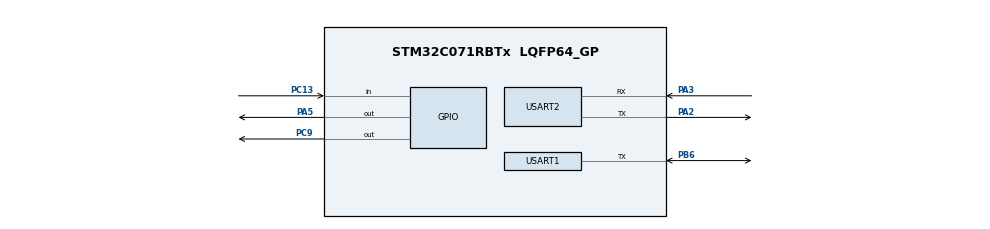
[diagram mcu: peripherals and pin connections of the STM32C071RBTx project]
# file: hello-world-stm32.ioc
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Mcu.Family=STM32C0
Mcu.Name=STM32C071RBTx
Mcu.Package=LQFP64_GP
NUCLEO-C071RB.BUTTON=1
NUCLEO-C071RB.LD1=true
NUCLEO-C071RB.LD2=true
NUCLEO-C071RB.VCP=false
NVIC.EXTI4_15_IRQn=true\:0\:0\:false\:false\:true\:false\:true\:true
NVIC.USART1_IRQn=true\:0\:0\:false\:false\:true\:true\:true\:true
NVIC.USART2_IRQn=true\:0\:0\:false\:false\:true\:true\:true\:true
PA13.Mode=Serial_Wire
PA13.Signal=DEBUG_SWDIO
PA14-BOOT0.Mode=Serial_Wire
PA14-BOOT0.Signal=DEBUG_SWCLK
PA2.Mode=Asynchronous
PA2.Signal=USART2_TX
PA3.Mode=Asynchronous
PA3.Signal=USART2_RX
PA5.Signal=GPIO_Output
PB6.Mode=Half_duplex(single_wire_mode)
PB6.Signal=USART1_TX
PB7.Signal=USART1_RX
PC13.Signal=GPIO_Input
PC9.Signal=GPIO_Output
ProjectManager.HeapSize=0x2000
ProjectManager.StackSize=0x400
ProjectManager.TargetToolchain=Makefile
RCC.ADCFreq_Value=48000000
RCC.AHBFreq_Value=48000000
RCC.CortexFreq_Value=48000000
RCC.EXTERNAL_CLOCK_VALUE=12288000
RCC.HCLKFreq_Value=48000000
RCC.HSE_VALUE=8000000
RCC.HSI48_VALUE=48000000
RCC.HSISYSCLKDivider=RCC_HSI_DIV1
RCC.HSI_VALUE=48000000
RCC.LSE_VALUE=32768
RCC.SYSCLKFreq_VALUE=48000000
USART1.DataInvertParam=ADVFEATURE_DATAINV_DISABLE
USART1.TxPinLevelInvertParam=ADVFEATURE_TXINV_DISABLE
USART1.VirtualMode-Half_duplex(single_wire_mode)=VM_ASYNC
USART2.VirtualMode-Asynchronous=VM_ASYNC
VP_NUCLEO-C071RB_VS_BSP_COMMON.Mode=COMMON
board=NUCLEO-C071RB

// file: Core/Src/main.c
/* USER CODE BEGIN Header */
/**
  ******************************************************************************
  * @file           : main.c
  * @brief          : Main program body
  ******************************************************************************
  * @attention
  *
  * Copyright (c) 2025 STMicroelectronics.
  * All rights reserved.
  *
  * This software is licensed under terms that can be found in the LICENSE file
  * in the root directory of this software component.
  * If no LICENSE file comes with this software, it is provided AS-IS.
  *
  ******************************************************************************
  */
/* USER CODE END Header */
#include "main.h"

/* USER CODE BEGIN Includes */
#include "StmSupervising.h"
/* USER CODE END Includes */

UART_HandleTypeDef huart1;
UART_HandleTypeDef huart2;

void SystemClock_Config(void);
static void MX_GPIO_Init(void);
static void MX_USART1_UART_Init(void);
static void MX_USART2_UART_Init(void);

int main(void)
{

  /* MCU Configuration--------------------------------------------------------*/

  /* Reset of all peripherals, Initializes the Flash interface and the Systick. */
  HAL_Init();

  /* Configure the system clock */
  SystemClock_Config();

  /* Initialize all configured peripherals */
  MX_GPIO_Init();
  MX_USART1_UART_Init();
  MX_USART2_UART_Init();

  /* Initialize leds */
  BSP_LED_Init(LED_GREEN);
  BSP_LED_Init(LED_BLUE);

  /* Initialize USER push-button, will be used to trigger an interrupt each time it's pressed.*/
  BSP_PB_Init(BUTTON_USER, BUTTON_MODE_EXTI);

  /* Infinite loop */
  /* USER CODE BEGIN WHILE */
  StmSupervising *pApp = StmSupervising::create();
  while (1)
  {
    pApp->treeTick();
    /* USER CODE END WHILE */

  }
}

void SystemClock_Config(void)
{
  RCC_OscInitTypeDef RCC_OscInitStruct = {0};
  RCC_ClkInitTypeDef RCC_ClkInitStruct = {0};

  __HAL_FLASH_SET_LATENCY(FLASH_LATENCY_1);

  /** Initializes the RCC Oscillators according to the specified parameters
  * in the RCC_OscInitTypeDef structure.
  */
  RCC_OscInitStruct.OscillatorType = RCC_OSCILLATORTYPE_HSI;
  RCC_OscInitStruct.HSIState = RCC_HSI_ON;
  RCC_OscInitStruct.HSIDiv = RCC_HSI_DIV1;
  RCC_OscInitStruct.HSICalibrationValue = RCC_HSICALIBRATION_DEFAULT;
  if (HAL_RCC_OscConfig(&RCC_OscInitStruct) != HAL_OK)
  {
    Error_Handler();
  }

  /** Initializes the CPU, AHB and APB buses clocks
  */
  RCC_ClkInitStruct.ClockType = RCC_CLOCKTYPE_HCLK|RCC_CLOCKTYPE_SYSCLK
                              |RCC_CLOCKTYPE_PCLK1;
  RCC_ClkInitStruct.SYSCLKSource = RCC_SYSCLKSOURCE_HSI;
  RCC_ClkInitStruct.SYSCLKDivider = RCC_SYSCLK_DIV1;
  RCC_ClkInitStruct.AHBCLKDivider = RCC_HCLK_DIV1;
  RCC_ClkInitStruct.APB1CLKDivider = RCC_APB1_DIV1;

  if (HAL_RCC_ClockConfig(&RCC_ClkInitStruct, FLASH_LATENCY_1) != HAL_OK)
  {
    Error_Handler();
  }
}

static void MX_USART1_UART_Init(void)
{

  huart1.Instance = USART1;
  huart1.Init.BaudRate = 115200;
  huart1.Init.WordLength = UART_WORDLENGTH_8B;
  huart1.Init.StopBits = UART_STOPBITS_1;
  huart1.Init.Parity = UART_PARITY_NONE;
  huart1.Init.Mode = UART_MODE_TX_RX;
  huart1.Init.HwFlowCtl = UART_HWCONTROL_NONE;
  huart1.Init.OverSampling = UART_OVERSAMPLING_16;
  huart1.Init.OneBitSampling = UART_ONE_BIT_SAMPLE_DISABLE;
  huart1.Init.ClockPrescaler = UART_PRESCALER_DIV1;
  huart1.AdvancedInit.AdvFeatureInit = UART_ADVFEATURE_NO_INIT;
  if (HAL_HalfDuplex_Init(&huart1) != HAL_OK)
  {
    Error_Handler();
  }
  if (HAL_UARTEx_SetTxFifoThreshold(&huart1, UART_TXFIFO_THRESHOLD_1_8) != HAL_OK)
  {
    Error_Handler();
  }
  if (HAL_UARTEx_SetRxFifoThreshold(&huart1, UART_RXFIFO_THRESHOLD_1_8) != HAL_OK)
  {
    Error_Handler();
  }
  if (HAL_UARTEx_DisableFifoMode(&huart1) != HAL_OK)
  {
    Error_Handler();
  }

}

static void MX_USART2_UART_Init(void)
{

  huart2.Instance = USART2;
  huart2.Init.BaudRate = 115200;
  huart2.Init.WordLength = UART_WORDLENGTH_8B;
  huart2.Init.StopBits = UART_STOPBITS_1;
  huart2.Init.Parity = UART_PARITY_NONE;
  huart2.Init.Mode = UART_MODE_TX_RX;
  huart2.Init.HwFlowCtl = UART_HWCONTROL_NONE;
  huart2.Init.OverSampling = UART_OVERSAMPLING_16;
  huart2.Init.OneBitSampling = UART_ONE_BIT_SAMPLE_DISABLE;
  huart2.Init.ClockPrescaler = UART_PRESCALER_DIV1;
  huart2.AdvancedInit.AdvFeatureInit = UART_ADVFEATURE_NO_INIT;
  if (HAL_UART_Init(&huart2) != HAL_OK)
  {
    Error_Handler();
  }
  if (HAL_UARTEx_SetTxFifoThreshold(&huart2, UART_TXFIFO_THRESHOLD_1_8) != HAL_OK)
  {
    Error_Handler();
  }
  if (HAL_UARTEx_SetRxFifoThreshold(&huart2, UART_RXFIFO_THRESHOLD_1_8) != HAL_OK)
  {
    Error_Handler();
  }
  if (HAL_UARTEx_DisableFifoMode(&huart2) != HAL_OK)
  {
    Error_Handler();
  }

}

static void MX_GPIO_Init(void)
{
  GPIO_InitTypeDef GPIO_InitStruct = {0};

  /* GPIO Ports Clock Enable */
  __HAL_RCC_GPIOC_CLK_ENABLE();
  __HAL_RCC_GPIOF_CLK_ENABLE();
  __HAL_RCC_GPIOA_CLK_ENABLE();
  __HAL_RCC_GPIOB_CLK_ENABLE();
  __HAL_RCC_GPIOD_CLK_ENABLE();

  /*Configure GPIO pins : PC11 PC12 PC14 PC15
                           PC0 PC1 PC2 PC3
                           PC4 PC5 PC6 PC7
                           PC8 PC10 */
  GPIO_InitStruct.Pin = GPIO_PIN_11|GPIO_PIN_12|GPIO_PIN_14|GPIO_PIN_15
                          |GPIO_PIN_0|GPIO_PIN_1|GPIO_PIN_2|GPIO_PIN_3
                          |GPIO_PIN_4|GPIO_PIN_5|GPIO_PIN_6|GPIO_PIN_7
                          |GPIO_PIN_8|GPIO_PIN_10;
  GPIO_InitStruct.Mode = GPIO_MODE_ANALOG;
  GPIO_InitStruct.Pull = GPIO_NOPULL;
  HAL_GPIO_Init(GPIOC, &GPIO_InitStruct);

  /*Configure GPIO pins : PF3 PF0 PF1 PF2 */
  GPIO_InitStruct.Pin = GPIO_PIN_3|GPIO_PIN_0|GPIO_PIN_1|GPIO_PIN_2;
  GPIO_InitStruct.Mode = GPIO_MODE_ANALOG;
  GPIO_InitStruct.Pull = GPIO_NOPULL;
  HAL_GPIO_Init(GPIOF, &GPIO_InitStruct);

  /*Configure GPIO pins : PA0 PA1 PA4 PA6
                           PA7 PA8 PA9 PA10
                           PA11 PA12 PA15 */
  GPIO_InitStruct.Pin = GPIO_PIN_0|GPIO_PIN_1|GPIO_PIN_4|GPIO_PIN_6
                          |GPIO_PIN_7|GPIO_PIN_8|GPIO_PIN_9|GPIO_PIN_10
                          |GPIO_PIN_11|GPIO_PIN_12|GPIO_PIN_15;
  GPIO_InitStruct.Mode = GPIO_MODE_ANALOG;
  GPIO_InitStruct.Pull = GPIO_NOPULL;
  HAL_GPIO_Init(GPIOA, &GPIO_InitStruct);

  /*Configure GPIO pins : PB0 PB1 PB2 PB10
                           PB11 PB12 PB13 PB14
                           PB15 PB3 PB4 PB5
                           PB8 PB9 */
  GPIO_InitStruct.Pin = GPIO_PIN_0|GPIO_PIN_1|GPIO_PIN_2|GPIO_PIN_10
                          |GPIO_PIN_11|GPIO_PIN_12|GPIO_PIN_13|GPIO_PIN_14
                          |GPIO_PIN_15|GPIO_PIN_3|GPIO_PIN_4|GPIO_PIN_5
                          |GPIO_PIN_8|GPIO_PIN_9;
  GPIO_InitStruct.Mode = GPIO_MODE_ANALOG;
  GPIO_InitStruct.Pull = GPIO_NOPULL;
  HAL_GPIO_Init(GPIOB, &GPIO_InitStruct);

  /*Configure GPIO pins : PD8 PD9 PD0 PD1
                           PD2 PD3 PD4 PD5
                           PD6 */
  GPIO_InitStruct.Pin = GPIO_PIN_8|GPIO_PIN_9|GPIO_PIN_0|GPIO_PIN_1
                          |GPIO_PIN_2|GPIO_PIN_3|GPIO_PIN_4|GPIO_PIN_5
                          |GPIO_PIN_6;
  GPIO_InitStruct.Mode = GPIO_MODE_ANALOG;
  GPIO_InitStruct.Pull = GPIO_NOPULL;
  HAL_GPIO_Init(GPIOD, &GPIO_InitStruct);

}

void Error_Handler(void)
{
  __disable_irq();
  while (1)
  {
  }
}
